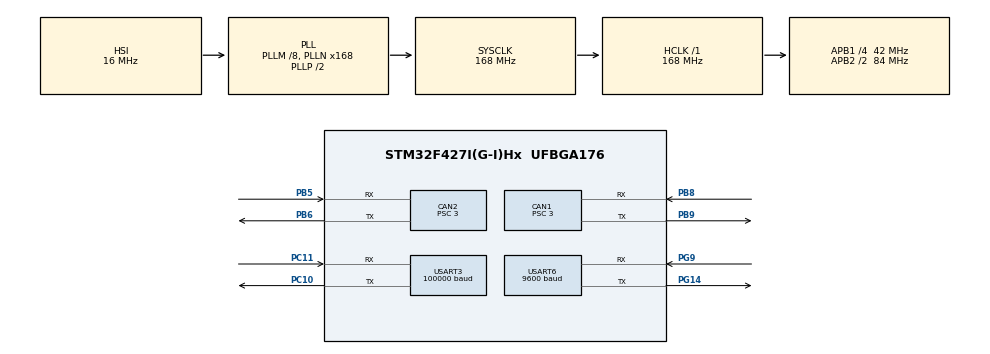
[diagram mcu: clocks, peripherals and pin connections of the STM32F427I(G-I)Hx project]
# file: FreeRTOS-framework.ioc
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CAN1.BS1=CAN_BS1_9TQ
CAN1.BS2=CAN_BS2_4TQ
CAN1.CalculateBaudRate=1000000
CAN1.CalculateTimeBit=1000
CAN1.CalculateTimeQuantum=71.42857142857143
CAN1.Prescaler=3
CAN2.BS1=CAN_BS1_9TQ
CAN2.BS2=CAN_BS2_4TQ
CAN2.CalculateBaudRate=1000000
CAN2.CalculateTimeBit=1000
CAN2.CalculateTimeQuantum=71.42857142857143
CAN2.Prescaler=3
Dma.Request0=USART3_RX
Dma.Request1=USART6_RX
Dma.USART3_RX.0.Direction=DMA_PERIPH_TO_MEMORY
Dma.USART3_RX.0.FIFOMode=DMA_FIFOMODE_DISABLE
Dma.USART3_RX.0.Instance=DMA1_Stream1
Dma.USART3_RX.0.MemDataAlignment=DMA_MDATAALIGN_BYTE
Dma.USART3_RX.0.MemInc=DMA_MINC_ENABLE
Dma.USART3_RX.0.Mode=DMA_CIRCULAR
Dma.USART3_RX.0.PeriphDataAlignment=DMA_PDATAALIGN_BYTE
Dma.USART3_RX.0.PeriphInc=DMA_PINC_DISABLE
Dma.USART3_RX.0.Priority=DMA_PRIORITY_LOW
Dma.USART6_RX.1.Direction=DMA_PERIPH_TO_MEMORY
Dma.USART6_RX.1.FIFOMode=DMA_FIFOMODE_DISABLE
Dma.USART6_RX.1.Instance=DMA2_Stream1
Dma.USART6_RX.1.MemDataAlignment=DMA_MDATAALIGN_BYTE
Dma.USART6_RX.1.MemInc=DMA_MINC_ENABLE
Dma.USART6_RX.1.Mode=DMA_CIRCULAR
Dma.USART6_RX.1.PeriphDataAlignment=DMA_PDATAALIGN_BYTE
Dma.USART6_RX.1.PeriphInc=DMA_PINC_DISABLE
Dma.USART6_RX.1.Priority=DMA_PRIORITY_HIGH
FREERTOS.Tasks01=StartTask,0,128,StartDefaultTask,Default,NULL,Dynamic,NULL,NULL
FREERTOS.configMAX_PRIORITIES=32
FREERTOS.configTOTAL_HEAP_SIZE=30720
Mcu.Family=STM32F4
Mcu.Name=STM32F427I(G-I)Hx
Mcu.Package=UFBGA176
NVIC.CAN1_RX0_IRQn=true\:5\:0\:false\:false\:true\:true\:true\:true\:true
NVIC.CAN2_RX0_IRQn=true\:5\:0\:false\:false\:true\:true\:true\:true\:true
NVIC.DMA1_Stream1_IRQn=true\:5\:0\:false\:false\:true\:true\:false\:true\:true
NVIC.DMA2_Stream1_IRQn=true\:5\:0\:false\:false\:true\:true\:false\:true\:true
NVIC.PriorityGroup=NVIC_PRIORITYGROUP_4
NVIC.TIM1_UP_TIM10_IRQn=true\:15\:0\:false\:false\:true\:false\:false\:true\:true
NVIC.TimeBase=TIM1_UP_TIM10_IRQn
NVIC.TimeBaseIP=TIM1
NVIC.USART3_IRQn=true\:5\:0\:false\:false\:true\:true\:true\:true\:true
NVIC.USART6_IRQn=true\:5\:0\:false\:false\:true\:true\:true\:true\:true
PA13.Mode=Serial_Wire
PA13.Signal=SYS_JTMS-SWDIO
PA14.Mode=Serial_Wire
PA14.Signal=SYS_JTCK-SWCLK
PB5.Mode=CAN_Activate
PB5.Signal=CAN2_RX
PB6.Mode=CAN_Activate
PB6.Signal=CAN2_TX
PB8.Mode=CAN_Activate
PB8.Signal=CAN1_RX
PB9.Mode=CAN_Activate
PB9.Signal=CAN1_TX
PC10.Mode=Asynchronous
PC10.Signal=USART3_TX
PC11.Mode=Asynchronous
PC11.Signal=USART3_RX
PG14.Mode=Asynchronous
PG14.Signal=USART6_TX
PG9.Mode=Asynchronous
PG9.Signal=USART6_RX
ProjectManager.HeapSize=0x200
ProjectManager.StackSize=0x400
ProjectManager.TargetToolchain=MDK-ARM V5.32
RCC.48MHZClocksFreq_Value=84000000
RCC.AHBFreq_Value=168000000
RCC.APB1CLKDivider=RCC_HCLK_DIV4
RCC.APB1Freq_Value=42000000
RCC.APB1TimFreq_Value=84000000
RCC.APB2CLKDivider=RCC_HCLK_DIV2
RCC.APB2Freq_Value=84000000
RCC.APB2TimFreq_Value=168000000
RCC.CortexFreq_Value=168000000
RCC.HCLKFreq_Value=168000000
RCC.HSE_VALUE=25000000
RCC.HSI_VALUE=16000000
RCC.LSE_VALUE=32768
RCC.PLLM=8
RCC.PLLN=168
RCC.SYSCLKFreq_VALUE=168000000
RCC.SYSCLKSource=RCC_SYSCLKSOURCE_PLLCLK
RCC.VCOOutputFreq_Value=336000000
USART3.BaudRate=100000
USART3.Parity=PARITY_EVEN
USART3.VirtualMode=VM_ASYNC
USART3.WordLength=WORDLENGTH_9B
USART6.BaudRate=9600
USART6.VirtualMode=VM_ASYNC
VP_FREERTOS_VS_CMSIS_V1.Mode=CMSIS_V1
VP_SYS_VS_tim1.Mode=TIM1
board=custom

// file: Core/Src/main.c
/* USER CODE BEGIN Header */
/**
  ******************************************************************************
  * @file           : main.c
  * @brief          : Main program body
  ******************************************************************************
  * @attention
  *
  * Copyright (c) 2026 STMicroelectronics.
  * All rights reserved.
  *
  * This software is licensed under terms that can be found in the LICENSE file
  * in the root directory of this software component.
  * If no LICENSE file comes with this software, it is provided AS-IS.
  *
  ******************************************************************************
  */
/* USER CODE END Header */
#include "main.h"
#include "cmsis_os.h"
#include "can.h"
#include "dma.h"
#include "usart.h"
#include "gpio.h"

/* USER CODE BEGIN Includes */
#include "bsp_can.h"
#include "bsp_rc.h"
#include "bsp_imu.h"
/* USER CODE END Includes */

void SystemClock_Config(void);
void MX_FREERTOS_Init(void);

int main(void)
{

  /* MCU Configuration--------------------------------------------------------*/

  /* Reset of all peripherals, Initializes the Flash interface and the Systick. */
  HAL_Init();

  /* Configure the system clock */
  SystemClock_Config();

  /* Initialize all configured peripherals */
  MX_GPIO_Init();
  MX_DMA_Init();
  MX_CAN1_Init();
  MX_CAN2_Init();
  MX_USART3_UART_Init();
  MX_USART6_UART_Init();
  /* USER CODE BEGIN 2 */
  CAN_Init();// 初始化 CAN 过滤器和中断
  RC_Init();//遥控器初始化
  IMU_Init();// 开启 USART6 DMA（IMU） 接收
  /* USER CODE END 2 */

  /* Call init function for freertos objects (in cmsis_os2.c) */
  MX_FREERTOS_Init();

  /* Start scheduler */
  osKernelStart();

  /* We should never get here as control is now taken by the scheduler */

  /* Infinite loop */
  while (1)
  {

  }
}

void SystemClock_Config(void)
{
  RCC_OscInitTypeDef RCC_OscInitStruct = {0};
  RCC_ClkInitTypeDef RCC_ClkInitStruct = {0};

  /** Configure the main internal regulator output voltage
  */
  __HAL_RCC_PWR_CLK_ENABLE();
  __HAL_PWR_VOLTAGESCALING_CONFIG(PWR_REGULATOR_VOLTAGE_SCALE1);

  /** Initializes the RCC Oscillators according to the specified parameters
  * in the RCC_OscInitTypeDef structure.
  */
  RCC_OscInitStruct.OscillatorType = RCC_OSCILLATORTYPE_HSI;
  RCC_OscInitStruct.HSIState = RCC_HSI_ON;
  RCC_OscInitStruct.HSICalibrationValue = RCC_HSICALIBRATION_DEFAULT;
  RCC_OscInitStruct.PLL.PLLState = RCC_PLL_ON;
  RCC_OscInitStruct.PLL.PLLSource = RCC_PLLSOURCE_HSI;
  RCC_OscInitStruct.PLL.PLLM = 8;
  RCC_OscInitStruct.PLL.PLLN = 168;
  RCC_OscInitStruct.PLL.PLLP = RCC_PLLP_DIV2;
  RCC_OscInitStruct.PLL.PLLQ = 4;
  if (HAL_RCC_OscConfig(&RCC_OscInitStruct) != HAL_OK)
  {
    Error_Handler();
  }

  /** Initializes the CPU, AHB and APB buses clocks
  */
  RCC_ClkInitStruct.ClockType = RCC_CLOCKTYPE_HCLK|RCC_CLOCKTYPE_SYSCLK
                              |RCC_CLOCKTYPE_PCLK1|RCC_CLOCKTYPE_PCLK2;
  RCC_ClkInitStruct.SYSCLKSource = RCC_SYSCLKSOURCE_PLLCLK;
  RCC_ClkInitStruct.AHBCLKDivider = RCC_SYSCLK_DIV1;
  RCC_ClkInitStruct.APB1CLKDivider = RCC_HCLK_DIV4;
  RCC_ClkInitStruct.APB2CLKDivider = RCC_HCLK_DIV2;

  if (HAL_RCC_ClockConfig(&RCC_ClkInitStruct, FLASH_LATENCY_5) != HAL_OK)
  {
    Error_Handler();
  }
}

void HAL_TIM_PeriodElapsedCallback(TIM_HandleTypeDef *htim)
{
  if (htim->Instance == TIM1)
  {
    HAL_IncTick();
  }
}

void Error_Handler(void)
{
  __disable_irq();
  while (1)
  {
  }
}

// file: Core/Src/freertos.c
/* USER CODE BEGIN Header */
/**
  ******************************************************************************
  * File Name          : freertos.c
  * Description        : Code for freertos applications
  ******************************************************************************
  * @attention
  *
  * Copyright (c) 2026 STMicroelectronics.
  * All rights reserved.
  *
  * This software is licensed under terms that can be found in the LICENSE file
  * in the root directory of this software component.
  * If no LICENSE file comes with this software, it is provided AS-IS.
  *
  ******************************************************************************
  */
/* USER CODE END Header */

#include "FreeRTOS.h"
#include "task.h"
#include "main.h"
#include "cmsis_os.h"

/* USER CODE BEGIN Includes */
#include "chassis_task.h"
#include "gimbal_task.h"
/* USER CODE END Includes */

osThreadId StartTaskHandle;

void StartDefaultTask(void const * argument);

void MX_FREERTOS_Init(void); /* (MISRA C 2004 rule 8.1) */

/* GetIdleTaskMemory prototype (linked to static allocation support) */
void vApplicationGetIdleTaskMemory( StaticTask_t **ppxIdleTaskTCBBuffer, StackType_t **ppxIdleTaskStackBuffer, uint32_t *pulIdleTaskStackSize );

/* USER CODE BEGIN GET_IDLE_TASK_MEMORY */
static StaticTask_t xIdleTaskTCBBuffer;
static StackType_t xIdleStack[configMINIMAL_STACK_SIZE];

void vApplicationGetIdleTaskMemory( StaticTask_t **ppxIdleTaskTCBBuffer, StackType_t **ppxIdleTaskStackBuffer, uint32_t *pulIdleTaskStackSize )
{
  *ppxIdleTaskTCBBuffer = &xIdleTaskTCBBuffer;
  *ppxIdleTaskStackBuffer = &xIdleStack[0];
  *pulIdleTaskStackSize = configMINIMAL_STACK_SIZE;
  /* place for user code */
}
/* USER CODE END GET_IDLE_TASK_MEMORY */

void MX_FREERTOS_Init(void) {

  /* Create the thread(s) */
  /* definition and creation of StartTask */
  osThreadDef(StartTask, StartDefaultTask, osPriorityNormal, 0, 128);
  StartTaskHandle = osThreadCreate(osThread(StartTask), NULL);

}

void StartDefaultTask(void const * argument)
{
  /* USER CODE BEGIN StartDefaultTask */

  // --- 1. 定义任务参数 ---
  // 参数说明：任务名(chassisTask), 入口函数(Chassis_Task), 优先级(Normal), 实例数(0), 栈大小(512)
  // 注意：我们将栈大小改为了 512，因为 PID 运算涉及浮点数，默认的 128 可能会导致栈溢出死机！
  osThreadDef(chassisTask, Chassis_Task, osPriorityNormal, 0, 512);

  // --- 2. 创建任务 ---
  // 这行代码执行完，底盘任务就开始运行了
  osThreadCreate(osThread(chassisTask), NULL);
  // 以下为云台代码
  osThreadDef(gimbalTask, Gimbal_Task, osPriorityHigh, 0, 512); // 云台优先级建议设高一点(High)
  osThreadCreate(osThread(gimbalTask), NULL);
  /* USER CODE END StartDefaultTask */
}
